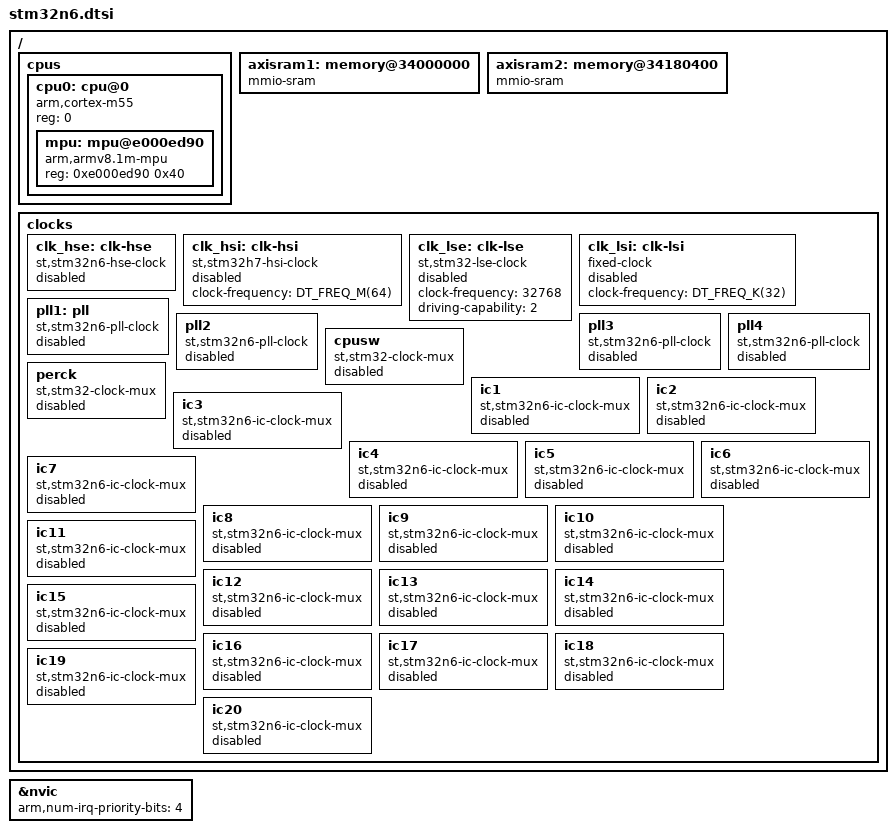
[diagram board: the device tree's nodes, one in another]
/*
 * Copyright (c) 2024 STMicroelectronics
 *
 * SPDX-License-Identifier: Apache-2.0
 */

#include <arm/armv8.1-m.dtsi>
#include <zephyr/dt-bindings/clock/stm32n6_clock.h>
#include <zephyr/dt-bindings/reset/stm32n6_reset.h>
#include <zephyr/dt-bindings/memory-controller/stm32-fmc-nor-psram.h>
#include <zephyr/dt-bindings/gpio/gpio.h>
#include <zephyr/dt-bindings/i2c/i2c.h>
#include <freq.h>

/ {
	cpus {
		#address-cells = <1>;
		#size-cells = <0>;

		cpu0: cpu@0 {
			device_type = "cpu";
			compatible = "arm,cortex-m55";
			reg = <0>;
			#address-cells = <1>;
			#size-cells = <1>;

			mpu: mpu@e000ed90 {
				compatible = "arm,armv8.1m-mpu";
				reg = <0xe000ed90 0x40>;
			};
		};
	};

	axisram1: memory@34000000 {
		compatible = "mmio-sram";
	};

	axisram2: memory@34180400 {
		compatible = "mmio-sram";
	};

	clocks {
		clk_hse: clk-hse {
			#clock-cells = <0>;
			compatible = "st,stm32n6-hse-clock";
			status = "disabled";
		};

		clk_hsi: clk-hsi {
			#clock-cells = <0>;
			compatible = "st,stm32h7-hsi-clock";
			clock-frequency = <DT_FREQ_M(64)>;
			status = "disabled";
		};

		clk_lse: clk-lse {
			#clock-cells = <0>;
			compatible = "st,stm32-lse-clock";
			clock-frequency = <32768>;
			driving-capability = <2>;
			status = "disabled";
		};

		clk_lsi: clk-lsi {
			#clock-cells = <0>;
			compatible = "fixed-clock";
			clock-frequency = <DT_FREQ_K(32)>;
			status = "disabled";
		};

		pll1: pll: pll {
			#clock-cells = <0>;
			compatible = "st,stm32n6-pll-clock";
			status = "disabled";
		};

		pll2: pll2 {
			#clock-cells = <0>;
			compatible = "st,stm32n6-pll-clock";
			status = "disabled";
		};

		pll3: pll3 {
			#clock-cells = <0>;
			compatible = "st,stm32n6-pll-clock";
			status = "disabled";
		};

		pll4: pll4 {
			#clock-cells = <0>;
			compatible = "st,stm32n6-pll-clock";
			status = "disabled";
		};

		cpusw: cpusw {
			#clock-cells = <0>;
			compatible = "st,stm32-clock-mux";
			status = "disabled";
		};

		perck: perck {
			#clock-cells = <0>;
			compatible = "st,stm32-clock-mux";
			status = "disabled";
		};

		ic1: ic1 {
			#clock-cells = <0>;
			compatible = "st,stm32n6-ic-clock-mux";
			status = "disabled";
		};

		ic2: ic2 {
			#clock-cells = <0>;
			compatible = "st,stm32n6-ic-clock-mux";
			status = "disabled";
		};

		ic3: ic3 {
			#clock-cells = <0>;
			compatible = "st,stm32n6-ic-clock-mux";
			status = "disabled";
		};

		ic4: ic4 {
			#clock-cells = <0>;
			compatible = "st,stm32n6-ic-clock-mux";
			status = "disabled";
		};

		ic5: ic5 {
			#clock-cells = <0>;
			compatible = "st,stm32n6-ic-clock-mux";
			status = "disabled";
		};

		ic6: ic6 {
			#clock-cells = <0>;
			compatible = "st,stm32n6-ic-clock-mux";
			status = "disabled";
		};

		ic7: ic7 {
			#clock-cells = <0>;
			compatible = "st,stm32n6-ic-clock-mux";
			status = "disabled";
		};

		ic8: ic8 {
			#clock-cells = <0>;
			compatible = "st,stm32n6-ic-clock-mux";
			status = "disabled";
		};

		ic9: ic9 {
			#clock-cells = <0>;
			compatible = "st,stm32n6-ic-clock-mux";
			status = "disabled";
		};

		ic10: ic10 {
			#clock-cells = <0>;
			compatible = "st,stm32n6-ic-clock-mux";
			status = "disabled";
		};

		ic11: ic11 {
			#clock-cells = <0>;
			compatible = "st,stm32n6-ic-clock-mux";
			status = "disabled";
		};

		ic12: ic12 {
			#clock-cells = <0>;
			compatible = "st,stm32n6-ic-clock-mux";
			status = "disabled";
		};

		ic13: ic13 {
			#clock-cells = <0>;
			compatible = "st,stm32n6-ic-clock-mux";
			status = "disabled";
		};

		ic14: ic14 {
			#clock-cells = <0>;
			compatible = "st,stm32n6-ic-clock-mux";
			status = "disabled";
		};

		ic15: ic15 {
			#clock-cells = <0>;
			compatible = "st,stm32n6-ic-clock-mux";
			status = "disabled";
		};

		ic16: ic16 {
			#clock-cells = <0>;
			compatible = "st,stm32n6-ic-clock-mux";
			status = "disabled";
		};

		ic17: ic17 {
			#clock-cells = <0>;
			compatible = "st,stm32n6-ic-clock-mux";
			status = "disabled";
		};

		ic18: ic18 {
			#clock-cells = <0>;
			compatible = "st,stm32n6-ic-clock-mux";
			status = "disabled";
		};

		ic19: ic19 {
			#clock-cells = <0>;
			compatible = "st,stm32n6-ic-clock-mux";
			status = "disabled";
		};

		ic20: ic20 {
			#clock-cells = <0>;
			compatible = "st,stm32n6-ic-clock-mux";
			status = "disabled";
		};
	};
};

&nvic {
	arm,num-irq-priority-bits = <4>;
};
